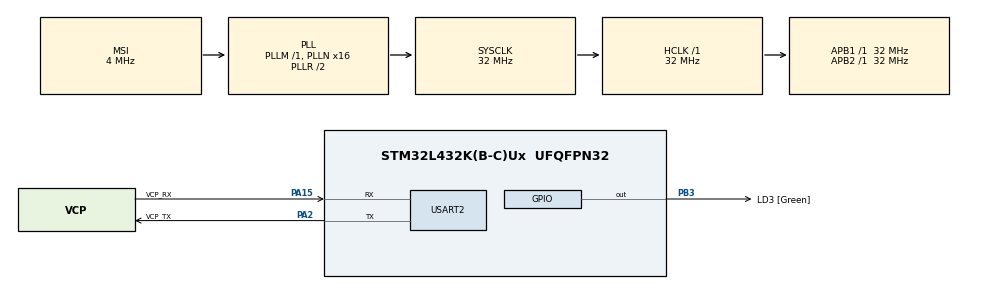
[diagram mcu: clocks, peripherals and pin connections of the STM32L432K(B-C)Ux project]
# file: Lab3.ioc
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Mcu.Family=STM32L4
Mcu.Name=STM32L432K(B-C)Ux
Mcu.Package=UFQFPN32
NVIC.PriorityGroup=NVIC_PRIORITYGROUP_4
NVIC.USART2_IRQn=true\:0\:0\:false\:false\:true\:true\:true\:true
PA0.GPIO_Label=MCO [High speed clock in]
PA0.Mode=HSE-External-Clock-Source-for-LittleOrca
PA0.Signal=RCC_CK_IN
PA13\ (JTMS-SWDIO).GPIO_Label=SWDIO
PA13\ (JTMS-SWDIO).Mode=Serial_Wire
PA13\ (JTMS-SWDIO).Signal=SYS_JTMS-SWDIO
PA14\ (JTCK-SWCLK).GPIO_Label=SWCLK
PA14\ (JTCK-SWCLK).Mode=Serial_Wire
PA14\ (JTCK-SWCLK).Signal=SYS_JTCK-SWCLK
PA15\ (JTDI).GPIO_Label=VCP_RX
PA15\ (JTDI).Mode=Asynchronous
PA15\ (JTDI).Signal=USART2_RX
PA2.GPIO_Label=VCP_TX
PA2.Mode=Asynchronous
PA2.Signal=USART2_TX
PB3\ (JTDO-TRACESWO).GPIO_Label=LD3 [Green]
PB3\ (JTDO-TRACESWO).Signal=GPIO_Output
PC14-OSC32_IN\ (PC14).Mode=LSE-External-Oscillator
PC14-OSC32_IN\ (PC14).Signal=RCC_OSC32_IN
PC15-OSC32_OUT\ (PC15).Mode=LSE-External-Oscillator
PC15-OSC32_OUT\ (PC15).Signal=RCC_OSC32_OUT
ProjectManager.HeapSize=0x200
ProjectManager.StackSize=0x400
ProjectManager.TargetToolchain=STM32CubeIDE
RCC.AHBFreq_Value=32000000
RCC.APB1Freq_Value=32000000
RCC.APB1TimFreq_Value=32000000
RCC.APB2Freq_Value=32000000
RCC.APB2TimFreq_Value=32000000
RCC.CortexFreq_Value=32000000
RCC.HCLKFreq_Value=32000000
RCC.HSE_VALUE=8000000
RCC.HSI16_VALUE=16000000
RCC.HSI48_VALUE=48000000
RCC.HSI_VALUE=16000000
RCC.MSI_VALUE=4000000
RCC.PLLMUL=RCC_PLLMUL_4
RCC.PLLN=16
RCC.SYSCLKFreq_VALUE=32000000
RCC.SYSCLKSource=RCC_SYSCLKSOURCE_PLLCLK
RCC.VCOOutputFreq_Value=64000000
USART2.VirtualMode-Asynchronous=VM_ASYNC
board=NUCLEO-L432KC

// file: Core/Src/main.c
/* USER CODE BEGIN Header */
/**
  ******************************************************************************
  * @file           : main.c
  * @brief          : Main program body
  ******************************************************************************
  * @attention
  *
  * Copyright (c) 2026 STMicroelectronics.
  * All rights reserved.
  *
  * This software is licensed under terms that can be found in the LICENSE file
  * in the root directory of this software component.
  * If no LICENSE file comes with this software, it is provided AS-IS.
  *
  ******************************************************************************
  */
/* USER CODE END Header */
#include "main.h"
#include "retarget.h"
#include "stm32l4xx_ll_usart.h"
#include "uart_rx_buffer.h"

/* USER CODE BEGIN Includes */
#include <string.h>
#include <stdio.h>
#include <stdint.h>
/* USER CODE END Includes */

/* USER CODE BEGIN PTD */
typedef struct command {
  char *cmd_string;
  void (*cmd_function)(char *arg);
} command_t;

/* USER CODE END PTD */

/* USER CODE BEGIN PD */
#define LINE_MAX 128
/* USER CODE END PD */

UART_HandleTypeDef huart2;
circ_buf_t g_rxbuf;
static uint8_t linebuf[LINE_MAX];
static uint16_t linelen = 0;
volatile uint32_t g_rx_irq_count = 0;

void SystemClock_Config(void);
static void MX_GPIO_Init(void);
static void MX_USART2_UART_Init(void);
/* USER CODE BEGIN PFP */
static void help_command(char *arguments);
static void lon_command(char *arguments);
static void lof_command(char *arguments);
static void test_command(char *arguments);
command_t commands[] = {
  {"help", help_command},
  {"lof",  lof_command},
  {"lon",  lon_command},
  {"test", test_command},
  {0, 0}
};
static int parse_command(uint8_t *line, uint8_t **command, uint8_t **args);
static int execute_command(uint8_t *line);
/* USER CODE END PFP */

int main(void)
{

  /* MCU Configuration--------------------------------------------------------*/

  /* Reset of all peripherals, Initializes the Flash interface and the Systick. */
  HAL_Init();

  /* Configure the system clock */
  SystemClock_Config();

  /* Initialize all configured peripherals */
  MX_GPIO_Init();
  MX_USART2_UART_Init();
  LL_USART_EnableIT_RXNE(USART2);
  RetargetInit(&huart2);

  /* USER CODE BEGIN 2 */
  rxbuf_init(&g_rxbuf);
  printf("System Up and Running\n\r");
  printf("> ");
  /* USER CODE END 2 */

  /* Infinite loop */
  while (1)
  {
	  uint8_t ch;
	  while (rxbuf_pop(&g_rxbuf, &ch) == 0) {

	    // convert CR to LF behavior
	    if (ch == '\r') {
	      printf("\r\n");

	      if (linelen < LINE_MAX) linebuf[linelen] = 0;

	      if (linelen > 0) {
	        if (execute_command(linebuf) == 0) {
	          printf("OK\r\n");
	        } else {
	          printf("NOK\r\n");
	        }
	      }

	      linelen = 0;
	      printf("> ");
	      continue;
	    }

	    // handle backspace
	    if (ch == 0x7F || ch == '\b') {
	      if (linelen > 0) {
	        linelen--;
	        printf("\b \b");
	      }
	      continue;
	    }

	    // echo and store normal char if space
	    if (linelen < (LINE_MAX - 1)) {
	      linebuf[linelen++] = ch;
	      printf("%c", ch);
	    }
	  }

  }
}

void SystemClock_Config(void)
{
  RCC_OscInitTypeDef RCC_OscInitStruct = {0};
  RCC_ClkInitTypeDef RCC_ClkInitStruct = {0};

  /** Configure the main internal regulator output voltage
  */
  if (HAL_PWREx_ControlVoltageScaling(PWR_REGULATOR_VOLTAGE_SCALE1) != HAL_OK)
  {
    Error_Handler();
  }

  /** Configure LSE Drive Capability
  */
  HAL_PWR_EnableBkUpAccess();
  __HAL_RCC_LSEDRIVE_CONFIG(RCC_LSEDRIVE_LOW);

  /** Initializes the RCC Oscillators according to the specified parameters
  * in the RCC_OscInitTypeDef structure.
  */
  RCC_OscInitStruct.OscillatorType = RCC_OSCILLATORTYPE_LSE|RCC_OSCILLATORTYPE_MSI;
  RCC_OscInitStruct.LSEState = RCC_LSE_ON;
  RCC_OscInitStruct.MSIState = RCC_MSI_ON;
  RCC_OscInitStruct.MSICalibrationValue = 0;
  RCC_OscInitStruct.MSIClockRange = RCC_MSIRANGE_6;
  RCC_OscInitStruct.PLL.PLLState = RCC_PLL_ON;
  RCC_OscInitStruct.PLL.PLLSource = RCC_PLLSOURCE_MSI;
  RCC_OscInitStruct.PLL.PLLM = 1;
  RCC_OscInitStruct.PLL.PLLN = 16;
  RCC_OscInitStruct.PLL.PLLP = RCC_PLLP_DIV7;
  RCC_OscInitStruct.PLL.PLLQ = RCC_PLLQ_DIV2;
  RCC_OscInitStruct.PLL.PLLR = RCC_PLLR_DIV2;
  if (HAL_RCC_OscConfig(&RCC_OscInitStruct) != HAL_OK)
  {
    Error_Handler();
  }

  /** Initializes the CPU, AHB and APB buses clocks
  */
  RCC_ClkInitStruct.ClockType = RCC_CLOCKTYPE_HCLK|RCC_CLOCKTYPE_SYSCLK
                              |RCC_CLOCKTYPE_PCLK1|RCC_CLOCKTYPE_PCLK2;
  RCC_ClkInitStruct.SYSCLKSource = RCC_SYSCLKSOURCE_PLLCLK;
  RCC_ClkInitStruct.AHBCLKDivider = RCC_SYSCLK_DIV1;
  RCC_ClkInitStruct.APB1CLKDivider = RCC_HCLK_DIV1;
  RCC_ClkInitStruct.APB2CLKDivider = RCC_HCLK_DIV1;

  if (HAL_RCC_ClockConfig(&RCC_ClkInitStruct, FLASH_LATENCY_1) != HAL_OK)
  {
    Error_Handler();
  }

  /** Enable MSI Auto calibration
  */
  HAL_RCCEx_EnableMSIPLLMode();
}

static void MX_USART2_UART_Init(void)
{

  huart2.Instance = USART2;
  huart2.Init.BaudRate = 115200;
  huart2.Init.WordLength = UART_WORDLENGTH_8B;
  huart2.Init.StopBits = UART_STOPBITS_1;
  huart2.Init.Parity = UART_PARITY_NONE;
  huart2.Init.Mode = UART_MODE_TX_RX;
  huart2.Init.HwFlowCtl = UART_HWCONTROL_NONE;
  huart2.Init.OverSampling = UART_OVERSAMPLING_16;
  huart2.Init.OneBitSampling = UART_ONE_BIT_SAMPLE_DISABLE;
  huart2.AdvancedInit.AdvFeatureInit = UART_ADVFEATURE_NO_INIT;
  if (HAL_UART_Init(&huart2) != HAL_OK)
  {
    Error_Handler();
  }

}

static void MX_GPIO_Init(void)
{
  GPIO_InitTypeDef GPIO_InitStruct = {0};

  /* GPIO Ports Clock Enable */
  __HAL_RCC_GPIOC_CLK_ENABLE();
  __HAL_RCC_GPIOA_CLK_ENABLE();
  __HAL_RCC_GPIOB_CLK_ENABLE();

  /*Configure GPIO pin Output Level */
  HAL_GPIO_WritePin(LD3_GPIO_Port, LD3_Pin, GPIO_PIN_RESET);

  /*Configure GPIO pin : LD3_Pin */
  GPIO_InitStruct.Pin = LD3_Pin;
  GPIO_InitStruct.Mode = GPIO_MODE_OUTPUT_PP;
  GPIO_InitStruct.Pull = GPIO_NOPULL;
  GPIO_InitStruct.Speed = GPIO_SPEED_FREQ_LOW;
  HAL_GPIO_Init(LD3_GPIO_Port, &GPIO_InitStruct);

}

/* USER CODE BEGIN 4 */
static int parse_command(uint8_t *line, uint8_t **command, uint8_t **args)
{
  if (!line || !command || !args) return -1;

  while (*line == ' ' || *line == '\t') line++;

  if (*line == 0) return -1;

  *command = line;

  uint8_t *p = line;
  while (*p && *p != ',') p++;

  if (*p == ',') {
    *p = 0;
    p++;
    *args = p;
  } else {
    *args = (uint8_t*)"";
  }

  return 0;
}

static int execute_command(uint8_t *line)
{
  uint8_t *cmd;
  uint8_t *arg;
  command_t *p = commands;
  int success = 0;

  if (!line) return -1;

  if (parse_command(line, &cmd, &arg) == -1) {
    printf("Error with parse command\r\n");
    return -1;
  }

  while (p->cmd_string) {
    if (!strcmp(p->cmd_string, (char*)cmd)) {
      if (!p->cmd_function) return -1;
      (*p->cmd_function)((char*)arg);
      success = 1;
      break;
    }
    p++;
  }

  if (success) return 0;
  return -1;
}

static void help_command(char *arguments)
{
  (void)arguments;
  printf("Available Commands:\r\n");
  for (command_t *p = commands; p->cmd_string; p++) {
    printf("%s\r\n", p->cmd_string);
  }
//  printf("rx_irq_count=%lu\r\n", g_rx_irq_count);
}

static void lon_command(char *arguments)
{
  (void)arguments;
  HAL_GPIO_WritePin(LD3_GPIO_Port, LD3_Pin, GPIO_PIN_SET);
}

static void lof_command(char *arguments)
{
  (void)arguments;
  HAL_GPIO_WritePin(LD3_GPIO_Port, LD3_Pin, GPIO_PIN_RESET);
}

static void test_command(char *arguments)
{
  if (!arguments || arguments[0] == 0) {
    return;
  }

  char *tok = strtok(arguments, ",");
  while (tok) {
    printf("%s\r\n", tok);
    tok = strtok(NULL, ",");
  }
}

/* USER CODE END 4 */

void Error_Handler(void)
{
  __disable_irq();
  while (1)
  {
  }
}
